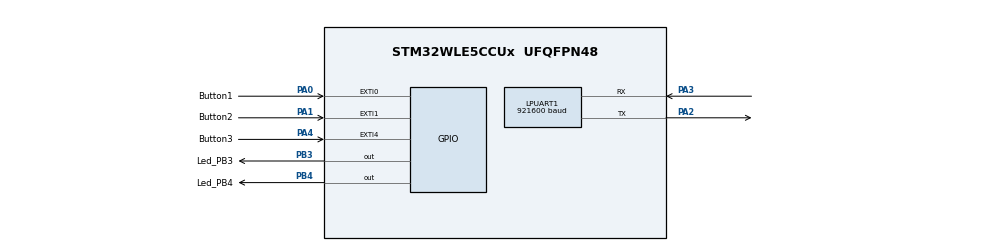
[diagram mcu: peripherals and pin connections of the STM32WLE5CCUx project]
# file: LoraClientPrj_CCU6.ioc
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FREERTOS.Tasks01=LoraTread,24,128,LoraTask,Default,NULL,Dynamic,NULL,NULL;LedBlinkThread,24,256,LedBlink,Default,NULL,Dynamic,NULL,NULL
LPUART1.BaudRate=921600
LPUART1.Mode=UART_MODE_TX
Mcu.Family=STM32WL
Mcu.Name=STM32WLE5CCUx
Mcu.Package=UFQFPN48
NVIC.EXTI0_IRQn=true\:5\:0\:false\:false\:true\:true\:true\:true\:true
NVIC.EXTI1_IRQn=true\:5\:0\:false\:false\:true\:true\:true\:true\:true
NVIC.EXTI4_IRQn=true\:5\:0\:false\:false\:true\:true\:true\:true\:true
NVIC.PriorityGroup=NVIC_PRIORITYGROUP_4
PA0.GPIO_Label=Button1
PA0.Signal=GPXTI0
PA1.GPIO_Label=Button2
PA1.Signal=GPXTI1
PA2.Mode=Asynchronous
PA2.Signal=LPUART1_TX
PA3.Mode=Asynchronous
PA3.Signal=LPUART1_RX
PA4.GPIO_Label=Button3
PA4.Signal=GPXTI4
PB3.GPIO_Label=Led_PB3
PB3.GPIO_PuPd=GPIO_PULLUP
PB3.Signal=GPIO_Output
PB4.GPIO_Label=Led_PB4
PB4.PinState=GPIO_PIN_SET
PB4.Signal=GPIO_Output
ProjectManager.HeapSize=0x200
ProjectManager.StackSize=0x400
ProjectManager.TargetToolchain=STM32CubeIDE
RCC.HSE_VALUE=8000000
RCC.HSI_VALUE=16000000
RCC.LSE_VALUE=32768
RCC.VCOOutputFreq_Value=32000000
SUBGHZ_PHY.Activate_RADIO_BOARD_INTERFACE=Bsp
SUBGHZ_PHY.USE_UART=false
VP_ADV_TRACE_VS_ADV_TRACE.Mode=ADV_TRACE_Enabled
VP_FREERTOS_VS_CMSIS_V2.Mode=CMSIS_V2
VP_MISC_VS_MISC.Mode=MISC_Enabled
VP_SUBGHZ_PHY_VS_SubGhzPhy.Mode=SubGhzPhy_Enabled
VP_SUBGHZ_VS_SUBGHZ.Mode=SUBGHZ_Activate
VP_TIMER_VS_TIMER.Mode=TIMER_Enabled
VP_TINY_LPM_VS_TINY_LPM.Mode=TINY_LPM_Enabled
board=custom

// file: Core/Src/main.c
/* USER CODE BEGIN Header */
/**
  ******************************************************************************
  * @file           : main.c
  * @brief          : Main program body
  ******************************************************************************
  * @attention
  *
  * Copyright (c) 2022 STMicroelectronics.
  * All rights reserved.
  *
  * This software is licensed under terms that can be found in the LICENSE file
  * in the root directory of this software component.
  * If no LICENSE file comes with this software, it is provided AS-IS.
  *
  ******************************************************************************
  */
/* USER CODE END Header */
#include "main.h"
#include "cmsis_os.h"
#include "app_lorawan.h"
#include "usart.h"
#include "gpio.h"

void SystemClock_Config(void);
void MX_FREERTOS_Init(void);

int main(void)
{

  /* MCU Configuration--------------------------------------------------------*/

  /* Reset of all peripherals, Initializes the Flash interface and the Systick. */
  HAL_Init();

  /* Configure the system clock */
  SystemClock_Config();

  /* Initialize all configured peripherals */
  MX_GPIO_Init();
  MX_LPUART1_UART_Init();
  /* USER CODE BEGIN 2 */
  HAL_GPIO_WritePin(Led_PB4_GPIO_Port, Led_PB4_Pin, GPIO_PIN_RESET);
  /* USER CODE END 2 */

  /* Init scheduler */
  osKernelInitialize();  /* Call init function for freertos objects (in freertos.c) */
  MX_FREERTOS_Init();

  /* Start scheduler */
  osKernelStart();

  /* We should never get here as control is now taken by the scheduler */
  /* Infinite loop */
  while (1)
  {

  }
}

void SystemClock_Config(void)
{
  RCC_OscInitTypeDef RCC_OscInitStruct = {0};
  RCC_ClkInitTypeDef RCC_ClkInitStruct = {0};

  /** Configure the main internal regulator output voltage
  */
  __HAL_PWR_VOLTAGESCALING_CONFIG(PWR_REGULATOR_VOLTAGE_SCALE2);

  /** Initializes the CPU, AHB and APB buses clocks
  */
  RCC_OscInitStruct.OscillatorType = RCC_OSCILLATORTYPE_MSI;
  RCC_OscInitStruct.MSIState = RCC_MSI_ON;
  RCC_OscInitStruct.MSICalibrationValue = RCC_MSICALIBRATION_DEFAULT;
  RCC_OscInitStruct.MSIClockRange = RCC_MSIRANGE_6;
  RCC_OscInitStruct.PLL.PLLState = RCC_PLL_NONE;
  if (HAL_RCC_OscConfig(&RCC_OscInitStruct) != HAL_OK)
  {
    Error_Handler();
  }

  /** Configure the SYSCLKSource, HCLK, PCLK1 and PCLK2 clocks dividers
  */
  RCC_ClkInitStruct.ClockType = RCC_CLOCKTYPE_HCLK3|RCC_CLOCKTYPE_HCLK
                              |RCC_CLOCKTYPE_SYSCLK|RCC_CLOCKTYPE_PCLK1
                              |RCC_CLOCKTYPE_PCLK2;
  RCC_ClkInitStruct.SYSCLKSource = RCC_SYSCLKSOURCE_MSI;
  RCC_ClkInitStruct.AHBCLKDivider = RCC_SYSCLK_DIV1;
  RCC_ClkInitStruct.APB1CLKDivider = RCC_HCLK_DIV1;
  RCC_ClkInitStruct.APB2CLKDivider = RCC_HCLK_DIV1;
  RCC_ClkInitStruct.AHBCLK3Divider = RCC_SYSCLK_DIV1;

  if (HAL_RCC_ClockConfig(&RCC_ClkInitStruct, FLASH_LATENCY_0) != HAL_OK)
  {
    Error_Handler();
  }
}

void Error_Handler(void)
{
  __disable_irq();
  while (1)
  {
  }
}

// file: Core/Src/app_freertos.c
/* USER CODE BEGIN Header */
/**
  ******************************************************************************
  * File Name          : app_freertos.c
  * Description        : Code for freertos applications
  ******************************************************************************
  * @attention
  *
  * Copyright (c) 2022 STMicroelectronics.
  * All rights reserved.
  *
  * This software is licensed under terms that can be found in the LICENSE file
  * in the root directory of this software component.
  * If no LICENSE file comes with this software, it is provided AS-IS.
  *
  ******************************************************************************
  */
/* USER CODE END Header */

#include "FreeRTOS.h"
#include "task.h"
#include "main.h"
#include "cmsis_os.h"

/* USER CODE BEGIN Includes */
#include "DebugLog.h"
/* USER CODE END Includes */

/* Definitions for LoraTread */
osThreadId_t LoraTreadHandle;
const osThreadAttr_t LoraTread_attributes = {
  .name = "LoraTread",
  .priority = (osPriority_t) osPriorityNormal,
  .stack_size = 128 * 4
};
/* Definitions for LedBlinkThread */
osThreadId_t LedBlinkThreadHandle;
const osThreadAttr_t LedBlinkThread_attributes = {
  .name = "LedBlinkThread",
  .priority = (osPriority_t) osPriorityNormal,
  .stack_size = 256 * 4
};

void LoraTask(void *argument);
void LedBlink(void *argument);

void MX_FREERTOS_Init(void); /* (MISRA C 2004 rule 8.1) */

void MX_FREERTOS_Init(void) {

  /* Create the thread(s) */
  /* creation of LoraTread */
  LoraTreadHandle = osThreadNew(LoraTask, NULL, &LoraTread_attributes);

  /* creation of LedBlinkThread */
  LedBlinkThreadHandle = osThreadNew(LedBlink, NULL, &LedBlinkThread_attributes);

}

void LoraTask(void *argument)
{
  /* USER CODE BEGIN LoraTask */
  /* Infinite loop */
  for(;;)
  {
    osDelay(1000);

  }
  /* USER CODE END LoraTask */
}

void LedBlink(void *argument)
{
  /* USER CODE BEGIN LedBlink */
  /* Infinite loop */
  for(;;)
  {
	  HAL_GPIO_TogglePin(Led_PB3_GPIO_Port, Led_PB3_Pin);
	  osDelay(1000);
	  DBG("hello world %.2f -\r\n",3.14);
  }
  /* USER CODE END LedBlink */
}
